# STM32G484VET6 register map
File version: 1.0
Registers are 32-bit, access not given, reset 0x0 unless marked. A register's access mark holds for its fields unless they carry their own. Offsets are from the block's base; [hi:lo] are bit positions; {n}, {i} and the like mark numbered series; 'fields as' and 'values as' point back to an identical list.

## DMA1
Base 0x40020000
Same registers: DMA2 0x40020400
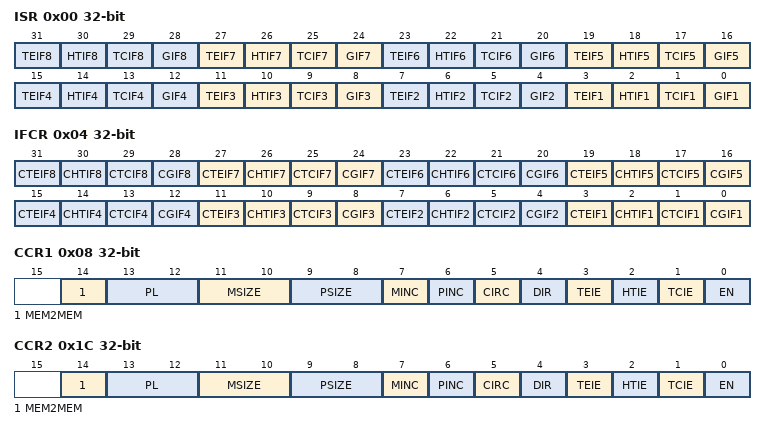
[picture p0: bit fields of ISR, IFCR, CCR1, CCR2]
0x00 ISR
  [4n-1] TEIF{n} (n=1..8), [4n-2] HTIF{n} (n=1..8), [4n-3] TCIF{n} (n=1..8), [4n-4] GIF{n} (n=1..8)
0x04 IFCR
  [4n-1] CTEIF{n} (n=1..8), [4n-2] CHTIF{n} (n=1..8), [4n-3] CTCIF{n} (n=1..8), [4n-4] CGIF{n} (n=1..8)
0x08 CCR1
  [14] MEM2MEM, [13:12] PL, [11:10] MSIZE, [9:8] PSIZE, [7] MINC, [6] PINC, [5] CIRC, [4] DIR, [3] TEIE, [2] HTIE, [1] TCIE, [0] EN
0x0C CNDTR1
  [15:0] NDT
0x10 CPAR1
  [31:0] PA
{0x0+0x14*i} CMAR{i} (i=1..8)
  [31:0] MA
0x1C CCR2
  fields as CCR1
0x20 CNDTR2
  [15:0] NDT
0x24 CPAR2
  [31:0] PA
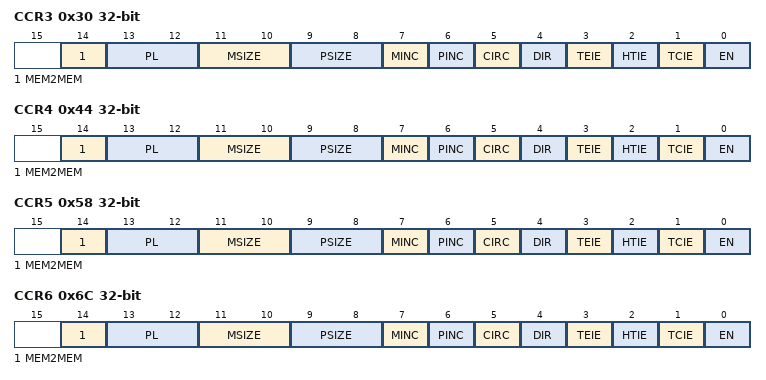
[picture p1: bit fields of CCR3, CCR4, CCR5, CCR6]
0x30 CCR3
  fields as CCR1
0x34 CNDTR3
  [15:0] NDT
0x38 CPAR3
  [31:0] PA
0x44 CCR4
  fields as CCR1
0x48 CNDTR4
  [15:0] NDT
0x4C CPAR4
  [31:0] PA
0x58 CCR5
  fields as CCR1
0x5C CNDTR5
  [15:0] NDT
0x60 CPAR5
  [31:0] PA
0x6C CCR6
  fields as CCR1
0x70 CNDTR6
  [15:0] NDT
0x74 CPAR6
  [31:0] PA
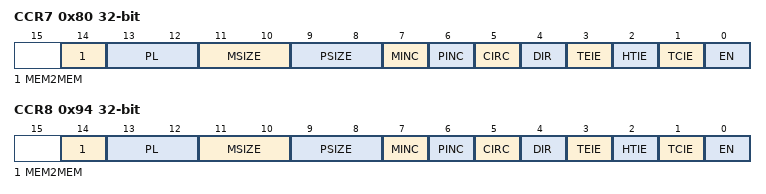
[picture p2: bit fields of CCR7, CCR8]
0x80 CCR7
  fields as CCR1
0x84 CNDTR7
  [15:0] NDT
0x88 CPAR7
  [31:0] PA
0x94 CCR8
  fields as CCR1
0x98 CNDTR8
  [15:0] NDT
0x9C CPAR8
  [31:0] PA

## DMAMUX1
Base 0x40020800
0x00 CCR0
0x04 CCR1
0x08 CCR2
0x0C CCR3
0x10 CCR4
0x14 CCR5
{0x0+4i} CCR{i} (i=6..9)
0x28 CCR0
0x2C CCR1
0x30 CCR2
0x34 CCR3
0x38 CCR4
0x3C CCR5
0x80 CCRs
0x100 CCR0
0x104 CCR1
0x108 CCR2
0x10C CCR3
0x140 CCRs

## CORDIC
Base 0x40020C00
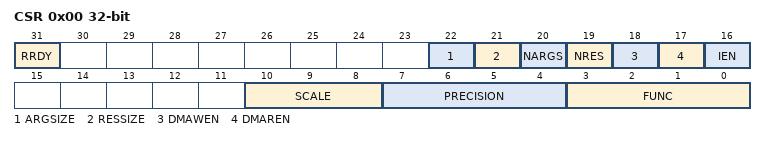
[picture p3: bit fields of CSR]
0x00 CSR
  [31] RRDY, [22] ARGSIZE, [21] RESSIZE, [20] NARGS, [19] NRES, [18] DMAWEN, [17] DMAREN, [16] IEN, [10:8] SCALE, [7:4] PRECISION, [3:0] FUNC
0x04 WDATA
  [31:0] ARG
0x08 RDATA
  [31:0] RES

## FMAC
Base 0x40021400
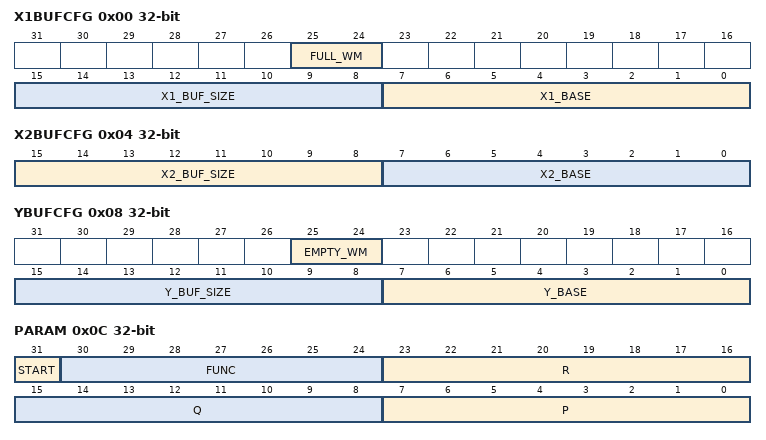
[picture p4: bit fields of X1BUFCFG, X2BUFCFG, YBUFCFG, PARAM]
0x00 X1BUFCFG
  [25:24] FULL_WM, [15:8] X1_BUF_SIZE, [7:0] X1_BASE
0x04 X2BUFCFG
  [15:8] X2_BUF_SIZE, [7:0] X2_BASE
0x08 YBUFCFG
  [25:24] EMPTY_WM, [15:8] Y_BUF_SIZE, [7:0] Y_BASE
0x0C PARAM
  [31] START, [30:24] FUNC, [23:16] R, [15:8] Q, [7:0] P
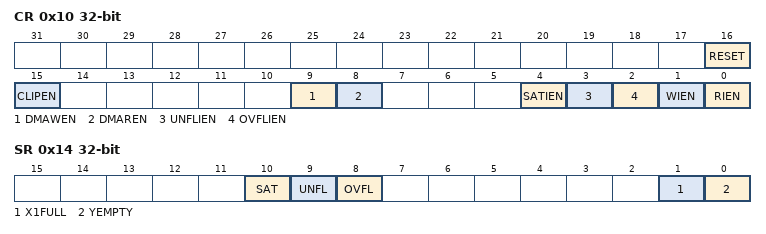
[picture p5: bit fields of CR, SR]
0x10 CR
  [16] RESET, [15] CLIPEN, [9] DMAWEN, [8] DMAREN, [4] SATIEN, [3] UNFLIEN, [2] OVFLIEN, [1] WIEN, [0] RIEN
0x14 SR
  [10] SAT, [9] UNFL, [8] OVFL, [1] X1FULL, [0] YEMPTY
0x18 WDATA
  [15:0] WDATA
0x1C RDATA
  [15:0] RDATA

## FLASH
Base 0x40022000
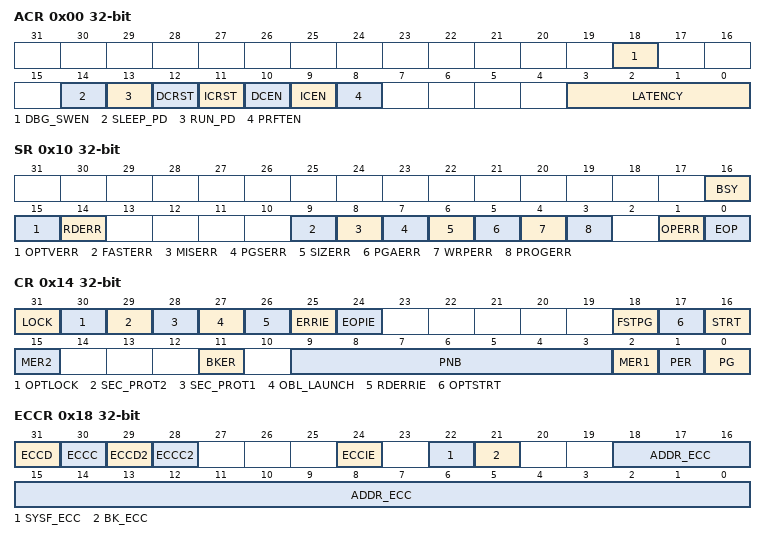
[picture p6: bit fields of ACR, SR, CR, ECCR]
0x00 ACR
  [18] DBG_SWEN, [14] SLEEP_PD, [13] RUN_PD, [12] DCRST, [11] ICRST, [10] DCEN, [9] ICEN, [8] PRFTEN, [3:0] LATENCY
0x04 PDKEYR
0x08 KEYR
0x0C OPTKEYR
0x10 SR
  [16] BSY, [15] OPTVERR, [14] RDERR, [9] FASTERR, [8] MISERR, [7] PGSERR, [6] SIZERR, [5] PGAERR, [4] WRPERR, [3] PROGERR, [1] OPERR, [0] EOP
0x14 CR
  [31] LOCK, [30] OPTLOCK, [29] SEC_PROT2, [28] SEC_PROT1, [27] OBL_LAUNCH, [26] RDERRIE, [25] ERRIE, [24] EOPIE, [18] FSTPG, [17] OPTSTRT, [16] STRT, [15] MER2, [11] BKER, [9:3] PNB, [2] MER1, [1] PER, [0] PG
0x18 ECCR
  [31] ECCD, [30] ECCC, [29] ECCD2, [28] ECCC2, [24] ECCIE, [22] SYSF_ECC, [21] BK_ECC, [18:0] ADDR_ECC
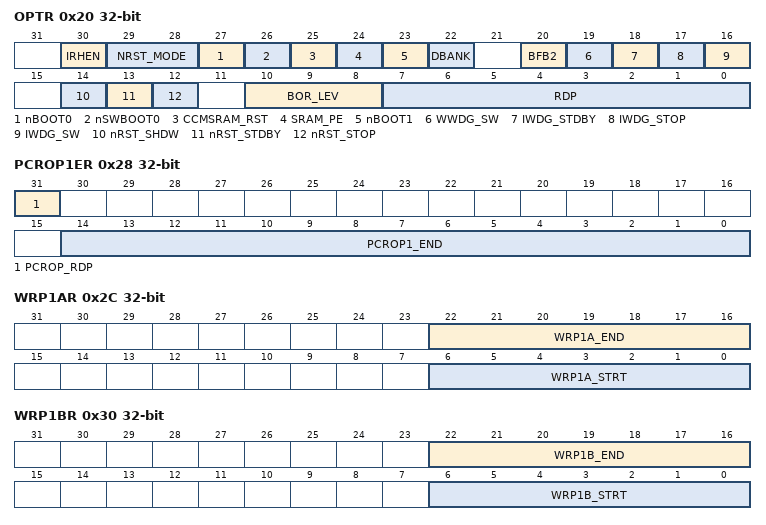
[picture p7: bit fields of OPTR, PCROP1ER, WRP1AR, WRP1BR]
0x20 OPTR
  [30] IRHEN, [29:28] NRST_MODE, [27] nBOOT0, [26] nSWBOOT0, [25] CCMSRAM_RST, [24] SRAM_PE, [23] nBOOT1, [22] DBANK, [20] BFB2, [19] WWDG_SW, [18] IWDG_STDBY, [17] IWDG_STOP, [16] IWDG_SW, [14] nRST_SHDW, [13] nRST_STDBY, [12] nRST_STOP, [10:8] BOR_LEV, [7:0] RDP
0x24 PCROP1SR
  [14:0] PCROP1_STRT
0x28 PCROP1ER
  [31] PCROP_RDP, [14:0] PCROP1_END
0x2C WRP1AR
  [22:16] WRP1A_END, [6:0] WRP1A_STRT
0x30 WRP1BR
  [22:16] WRP1B_END, [6:0] WRP1B_STRT
0x44 PCROP2SR
  [14:0] PCROP2_STRT
0x48 PCROP2ER
  [14:0] PCROP2_END
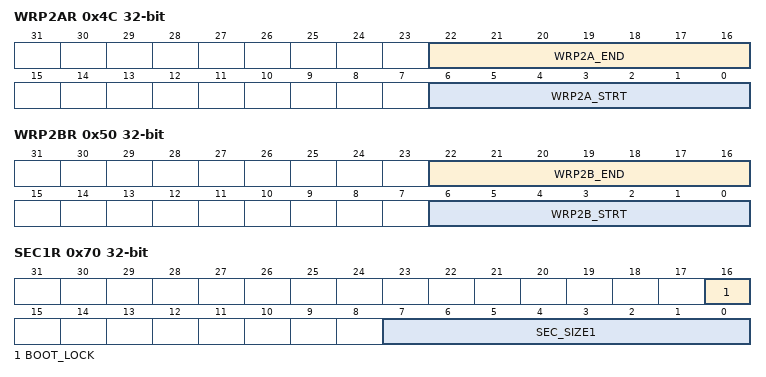
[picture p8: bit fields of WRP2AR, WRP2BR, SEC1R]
0x4C WRP2AR
  [22:16] WRP2A_END, [6:0] WRP2A_STRT
0x50 WRP2BR
  [22:16] WRP2B_END, [6:0] WRP2B_STRT
0x70 SEC1R
  [16] BOOT_LOCK, [7:0] SEC_SIZE1
0x74 SEC2R
  [7:0] SEC_SIZE2

## CRC
Base 0x40023000
0x00 DR
0x04 IDR
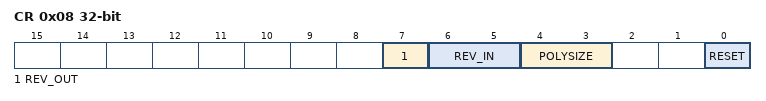
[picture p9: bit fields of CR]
0x08 CR
  [7] REV_OUT, [6:5] REV_IN, [4:3] POLYSIZE, [0] RESET
0x10 INIT
0x14 POL

## GPIOA
Base 0x48000000
Same registers: GPIOB 0x48000400, GPIOC 0x48000800, GPIOD 0x48000C00, GPIOE 0x48001000, GPIOF 0x48001400, GPIOG 0x48001800
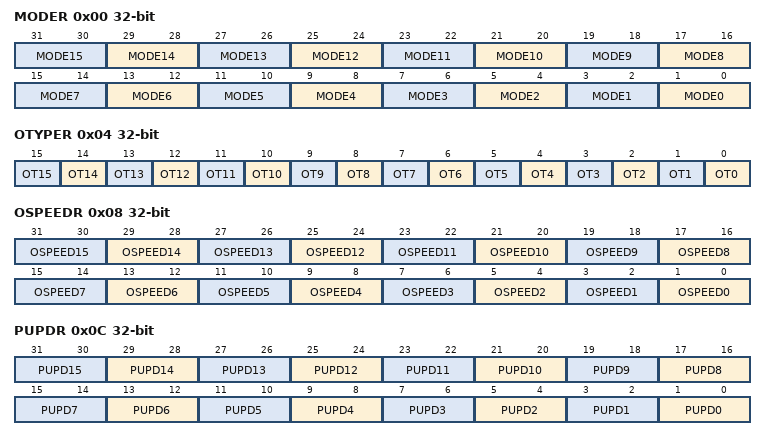
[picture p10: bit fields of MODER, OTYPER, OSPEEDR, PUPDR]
0x00 MODER
  [2n+1:2n] MODE{n} (n=0..15)
0x04 OTYPER
  [n] OT{n} (n=0..15)
0x08 OSPEEDR
  [2n+1:2n] OSPEED{n} (n=0..15)
0x0C PUPDR
  [2n+1:2n] PUPD{n} (n=0..15)
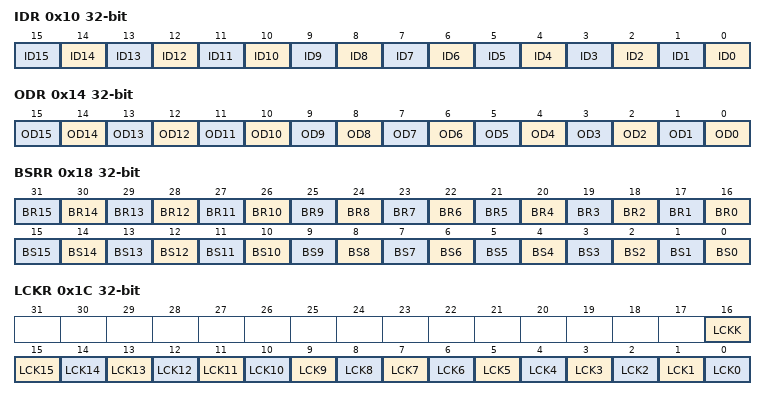
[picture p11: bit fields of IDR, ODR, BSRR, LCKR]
0x10 IDR
  [n] ID{n} (n=0..15)
0x14 ODR
  [n] OD{n} (n=0..15)
0x18 BSRR
  [n+16] BR{n} (n=0..15), [n] BS{n} (n=0..15)
0x1C LCKR
  [16] LCKK, [n] LCK{n} (n=0..15)
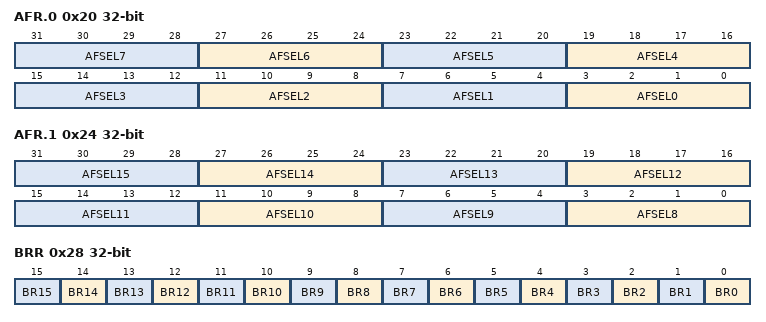
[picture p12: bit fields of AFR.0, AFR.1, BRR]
0x20 AFR.0
  [4n+3:4n] AFSEL{n} (n=0..7)
0x24 AFR.1
  [4n-29:4n-32] AFSEL{n} (n=8..15)
0x28 BRR
  [n] BR{n} (n=0..15)
